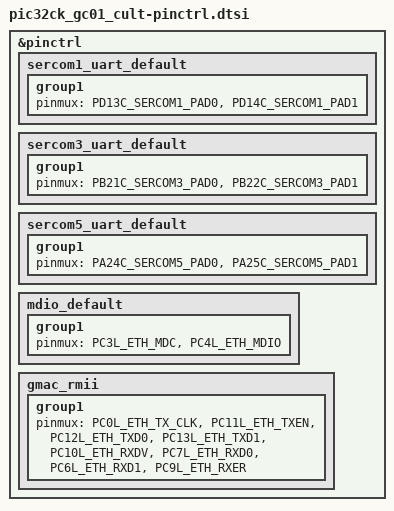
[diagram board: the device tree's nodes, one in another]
/*
 * SPDX-FileCopyrightText: Copyright (c) 2026 Microchip Technology Inc.
 *
 * SPDX-License-Identifier: Apache-2.0
 */

#include <dt-bindings/pic32c/pic32ck_sg_gc/pic32ck_gc01/pic32ck2051gc01144-pinctrl.h>

&pinctrl {
	sercom1_uart_default: sercom1_uart_default {
		group1 {
			pinmux = <PD13C_SERCOM1_PAD0>, /* TX */
				 <PD14C_SERCOM1_PAD1>; /* RX */
		};
	};

	sercom3_uart_default: sercom3_uart_default {
		group1 {
			pinmux = <PB21C_SERCOM3_PAD0>, /* TX */
				 <PB22C_SERCOM3_PAD1>; /* RX */
		};
	};

	sercom5_uart_default: sercom5_uart_default {
		group1 {
			pinmux = <PA24C_SERCOM5_PAD0>, /* TX */
				 <PA25C_SERCOM5_PAD1>; /* RX */
		};
	};

	mdio_default: mdio_default {
		group1 {
			pinmux = <PC3L_ETH_MDC>,
				 <PC4L_ETH_MDIO>;
		};
	};

	gmac_rmii: gmac_rmii {
		group1 {
			pinmux = <PC0L_ETH_TX_CLK>,
				 <PC11L_ETH_TXEN>,
				 <PC12L_ETH_TXD0>,
				 <PC13L_ETH_TXD1>,
				 <PC10L_ETH_RXDV>,
				 <PC7L_ETH_RXD0>,
				 <PC6L_ETH_RXD1>,
				 <PC9L_ETH_RXER>;
		};
	};
};
